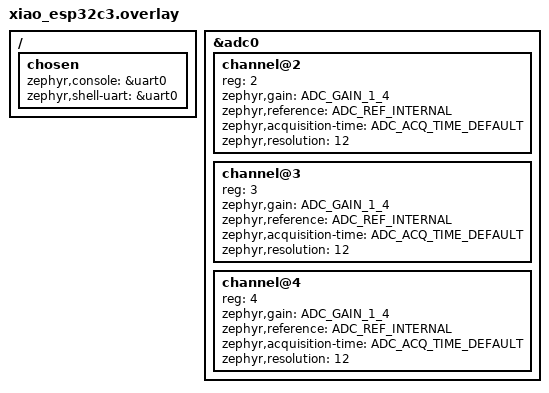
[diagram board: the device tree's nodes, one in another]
/ {
    chosen {
        zephyr,console = &uart0;
        zephyr,shell-uart = &uart0;
    };
};

// D0-D2 are GPIO2-4, ADC1 channels 2-4.
// D3 (GPIO5) isn't ADC-capable on this chip.
&adc0 {
    status = "okay";
    #address-cells = <1>;
    #size-cells = <0>;

    channel@2 {
        reg = <2>; /* D0, GPIO2 */
        zephyr,gain = "ADC_GAIN_1_4";
        zephyr,reference = "ADC_REF_INTERNAL";
        zephyr,acquisition-time = <ADC_ACQ_TIME_DEFAULT>;
        zephyr,resolution = <12>;
    };

    channel@3 {
        reg = <3>; /* D1, GPIO3 */
        zephyr,gain = "ADC_GAIN_1_4";
        zephyr,reference = "ADC_REF_INTERNAL";
        zephyr,acquisition-time = <ADC_ACQ_TIME_DEFAULT>;
        zephyr,resolution = <12>;
    };

    channel@4 {
        reg = <4>; /* D2, GPIO4 */
        zephyr,gain = "ADC_GAIN_1_4";
        zephyr,reference = "ADC_REF_INTERNAL";
        zephyr,acquisition-time = <ADC_ACQ_TIME_DEFAULT>;
        zephyr,resolution = <12>;
    };
};
